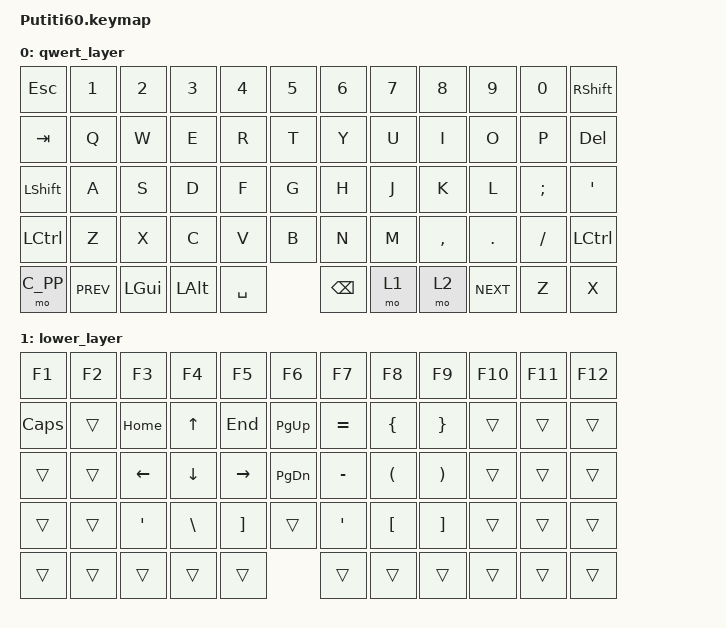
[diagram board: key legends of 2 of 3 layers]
#include <behaviors.dtsi>
#include <dt-bindings/zmk/bt.h>
#include <dt-bindings/zmk/keys.h>

#define DEFAULT 0
#define LOWER 1
#define RAISE 2
#define TOGGLE 3
#define L4 4
#define MAC 5
#define MAC_LOWER 6
#define MAC_RAISE 7
#define MAC_L4

&lt {
        flavor = "balanced";
        tapping-term-ms = <150>;
};

/ {
        behaviors {
                td0: tap_dance_0 {
                        compatible = "zmk,behavior-tap-dance";
                        label = "TAP_DANCE_0";
                        #binding-cells = <0>;
                        tapping-term-ms = <200>;
                        bindings = <&kp LSHIFT>, <&kp CAPS>;
                };
                mo_tog: behavior_mo_tog {
                        compatible = "zmk,behavior-hold-tap";
                        label = "mo_tog";
                        flavor = "hold-preferred";
                        #binding-cells = <2>;
                        tapping-term-ms = <200>;
                        bindings = <&mo>, <&tog>;
                };        
        };


	keymap {
		compatible = "zmk,keymap";

		qwert_layer {
			bindings = <
                   &kp ESC   &kp N1      &kp N2    &kp N3    &kp N4    &kp N5 &kp N6    &kp N7  &kp N8     &kp N9     &kp N0    &kp RSHFT
                   &kp TAB   &kp Q       &kp W     &kp E     &kp R     &kp T  &kp Y     &kp U   &kp I      &kp O      &kp P     &kp DEL
                   &kp LSHFT &kp A       &kp S     &kp D     &kp F     &kp G  &kp H     &kp J   &kp K      &kp L      &kp SEMI  &kp SQT
                   &kp LCTRL &kp Z       &kp X     &kp C     &kp V     &kp B  &kp N     &kp M   &kp COMMA  &kp DOT    &kp FSLH  &kp LCTRL
		           &mo C_PP  &kp C_PREV  &kp LGUI  &kp LALT  &kp SPACE        &kp BSPC  &mo 1   &mo 2      &kp C_NEXT &kp Z     &kp X
			>;
		};

		lower_layer {
			bindings = <
               &kp F1   &kp F2  &kp F3    &kp F4    &kp F5    &kp F6         &kp F7      &kp F8    &kp F9    &kp F10  &kp F11 &kp F12
               &kp CAPS &trans  &kp HOME  &kp UP    &kp END   &kp PAGE_UP    &kp EQUAL   &kp LBRC  &kp RBRC  &trans   &trans  &trans
               &trans   &trans  &kp LEFT  &kp DOWN  &kp RIGHT &kp PAGE_DOWN  &kp MINUS   &kp LPAR  &kp RPAR  &trans   &trans  &trans   
               &trans   &trans  &kp SQT   &kp BSLH  &kp RBKT  &trans         &kp SQT     &kp LBKT  &kp RBKT  &trans   &trans  &trans
               &trans   &trans  &trans    &trans    &trans        &trans                 &trans    &trans    &trans   &trans  &trans
                        >; 
                };

		raise_layer {
			bindings = <
                &trans  &trans   &trans    &trans    &trans    &trans     &trans          &trans  &trans  &trans  &trans   &kp C_VOL_UP
                &trans  &kp EXCL &kp AT    &kp HASH  &kp DLLR  &kp PRCNT  &kp GRAVE       &trans  &trans  &trans  &trans   &kp C_VOL_DN
                &trans  &kp PIPE &kp BSLH  &kp AMPS  &kp STAR  &kp CARET  &kp LS(LA(UP))  &trans  &trans  &trans  &trans   &trans 
                &trans  &trans   &trans    &trans    &trans       &trans                  &trans  &trans  &trans  &trans   &trans
                        >;
		};
    };
};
